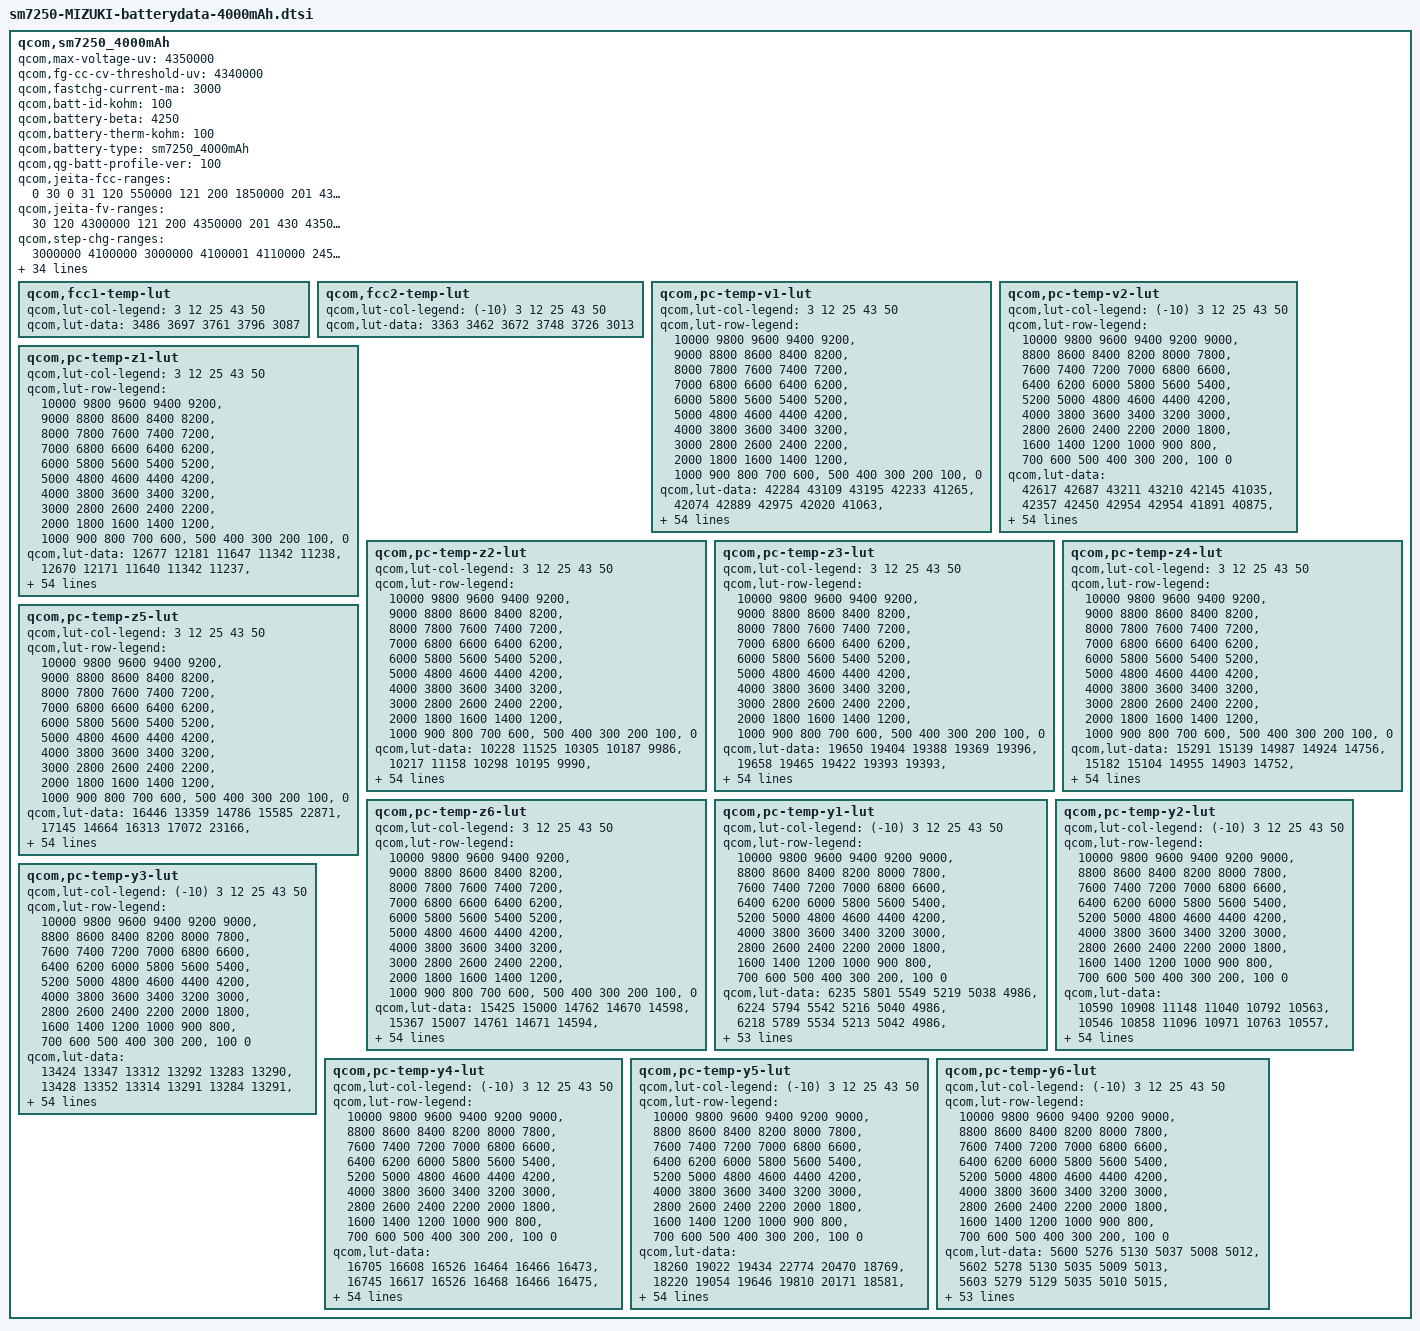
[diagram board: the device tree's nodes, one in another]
/*
 * This software is contributed or developed by KYOCERA Corporation.
 * (C) 2020 KYOCERA Corporation
 *
 * This program is free software; you can redistribute it and/or modify
 * it under the terms of the GNU General Public License version 2 and
 * only version 2 as published by the Free Software Foundation.
 *
 * This program is distributed in the hope that it will be useful,
 * but WITHOUT ANY WARRANTY; without even the implied warranty of
 * MERCHANTABILITY or FITNESS FOR A PARTICULAR PURPOSE.  See the
 * GNU General Public License for more details.
 */

qcom,sm7250_4000mAh {
	qcom,max-voltage-uv = <4350000>;
	qcom,fg-cc-cv-threshold-uv = <4340000>;
	qcom,fastchg-current-ma = <3000>;
	qcom,batt-id-kohm = <100>;
	qcom,battery-beta = <4250>;
	qcom,battery-therm-kohm = <100>;
	qcom,battery-type = "sm7250_4000mAh";
	qcom,qg-batt-profile-ver = <100>;

	qcom,jeita-fcc-ranges = <0  30  0
				 31 120  550000
				121 200  1850000
				201 430  3000000
				431 500  1850000
				501 600  0>;

	qcom,jeita-fv-ranges = <30 120  4300000
				121 200  4350000
				201 430  4350000
				431 500  4150000>;

	qcom,step-chg-ranges = <3000000  4100000  3000000
				4100001  4110000  2450000
				4110001  4120000  2450000
				4120001  4130000  2450000
				4130001  4140000  2450000
				4140001  4150000  2450000
				4150001  4350000  1200000>;
	qcom,step-chg-ranges-cool = <3000000  4350000  550000>;
	qcom,step-chg-ranges-weekcool = <3000000  4100000  1850000
				4100001  4150000  1450000
				4150001  4350000  1000000>;
	qcom,step-chg-ranges-normal = <3000000  4150000  3000000
				4150001  4250000  2250000
				4250001  4350000  1000000>;
	qcom,step-chg-ranges-warm = <3000000  4350000  1850000>;
	qcom,step-chg-temp-thresh = <30 100 200 430>;
	qcom,ocv-based-step-chg;

	/* COOL = 12 DegC, WARM = 43 DegC */
	qcom,jeita-soft-thresholds = <0x4A2A 0x22B8>;
	/* COLD = 3 DegC, HOT = 50 DegC */
	qcom,jeita-hard-thresholds = <0x5571 0x1C22>;
	/* COOL hys = 14 DegC, WARM hys = 41 DegC */
	qcom,jeita-soft-hys-thresholds = <0x477C 0x24CF>;
	qcom,jeita-soft-fcc-ua = <560000 1850000>;
	qcom,jeita-soft-fv-uv = <4300000 4150000>;

	oem,batt-capacity-mah = <4000>;
	oem,deterioration-thresh-good = <75>;
	oem,deterioration-thresh-norm = <50>;
	oem,deterioration-thresh-normtogood = <85>;
	oem,deterioration-thresh-deadtonorm = <60>;
	oem,cycle-count-thresh = <50 100 200 400 600>;
	oem,cycle-count-voltage-comp-mv = <40 80 120 160 200>;
	oem,cont-chg-thresh = <520000 840000 1200000 2200000 3300000>;
	oem,cont-chg-voltage-comp-mv = <40 80 120 160 200>;
	oem,batt-temp-thresh = <(-1250) 300 320 340 360 380 400 420 440 460>;
	oem,cont-chg-factor = <29 42 60 86 124 180 261 378 549 783>;
	oem,cont-chg-factor-batt-care = <15 21 30 43 62 90 131 189 275 392>;
	oem,batt-care-max-voltage-uv = <4200000>;

	qcom,fcc1-temp-lut {
		qcom,lut-col-legend = <3 12 25 43 50>;
		qcom,lut-data = <3486 3697 3761 3796 3087>;
	};

	qcom,fcc2-temp-lut {
		qcom,lut-col-legend = <(-10) 3 12 25 43 50>;
		qcom,lut-data = <3363 3462 3672 3748 3726 3013>;
	};

	qcom,pc-temp-v1-lut {
		qcom,lut-col-legend = <3 12 25 43 50>;
		qcom,lut-row-legend = <10000 9800 9600 9400 9200>,
			<9000 8800 8600 8400 8200>,
			<8000 7800 7600 7400 7200>,
			<7000 6800 6600 6400 6200>,
			<6000 5800 5600 5400 5200>,
			<5000 4800 4600 4400 4200>,
			<4000 3800 3600 3400 3200>,
			<3000 2800 2600 2400 2200>,
			<2000 1800 1600 1400 1200>,
			<1000 900 800 700 600>,
			<500 400 300 200 100>,
			<0>;
		qcom,lut-data = <42284 43109 43195 42233 41265>,
			<42074 42889 42975 42020 41063>,
			<41859 42668 42756 41806 40851>,
			<41643 42448 42540 41593 40638>,
			<41445 42231 42324 41379 40422>,
			<41282 42022 42111 41165 40205>,
			<41143 41816 41899 40951 39991>,
			<40998 41613 41690 40737 39778>,
			<40824 41412 41484 40527 39568>,
			<40621 41217 41279 40320 39361>,
			<40405 41040 41080 40117 39158>,
			<40181 40877 40892 39923 38960>,
			<39953 40706 40712 39734 38765>,
			<39742 40494 40530 39552 38578>,
			<39564 40264 40343 39372 38396>,
			<39411 40079 40160 39196 38220>,
			<39261 39950 40000 39031 38053>,
			<39099 39829 39865 38887 37905>,
			<38929 39660 39714 38737 37758>,
			<38773 39418 39496 38538 37573>,
			<38640 39187 39241 38287 37329>,
			<38522 39028 39048 38074 37106>,
			<38425 38904 38921 37932 36954>,
			<38352 38799 38815 37814 36831>,
			<38290 38710 38709 37707 36720>,
			<38233 38630 38609 37609 36619>,
			<38178 38550 38518 37519 36526>,
			<38129 38472 38436 37434 36439>,
			<38083 38398 38362 37354 36356>,
			<38042 38335 38294 37282 36280>,
			<38002 38278 38232 37218 36213>,
			<37962 38227 38175 37159 36150>,
			<37925 38183 38125 37104 36090>,
			<37885 38144 38079 37050 36030>,
			<37847 38108 38036 36998 35972>,
			<37810 38077 37997 36946 35913>,
			<37761 38043 37958 36894 35852>,
			<37698 37994 37907 36831 35781>,
			<37633 37919 37831 36748 35689>,
			<37559 37829 37740 36652 35584>,
			<37433 37730 37642 36550 35477>,
			<37296 37612 37530 36437 35365>,
			<37203 37474 37398 36301 35229>,
			<37114 37323 37248 36142 35064>,
			<37030 37193 37129 36036 34968>,
			<36953 37121 37053 35980 34921>,
			<36950 37100 37033 35957 34899>,
			<36931 37084 37017 35938 34880>,
			<36858 37062 36993 35914 34855>,
			<36697 36986 36915 35822 34750>,
			<36686 36737 36647 35516 34426>,
			<35946 36292 36201 35076 33989>,
			<35605 35730 35639 34516 33428>,
			<34343 34981 34884 33760 32669>,
			<33008 33773 33683 32559 31471>,
			<30000 30000 30000 30000 30000>;
	};

	qcom,pc-temp-v2-lut {
		qcom,lut-col-legend = <(-10) 3 12 25 43 50>;
		qcom,lut-row-legend = <10000 9800 9600 9400 9200 9000>,
			<8800 8600 8400 8200 8000 7800>,
			<7600 7400 7200 7000 6800 6600>,
			<6400 6200 6000 5800 5600 5400>,
			<5200 5000 4800 4600 4400 4200>,
			<4000 3800 3600 3400 3200 3000>,
			<2800 2600 2400 2200 2000 1800>,
			<1600 1400 1200 1000 900 800>,
			<700 600 500 400 300 200>,
			<100 0>;
		qcom,lut-data = <42617 42687 43211 43210 42145 41035>,
			<42357 42450 42954 42954 41891 40875>,
			<42125 42125 42706 42708 41648 40720>,
			<41907 42020 42471 42473 41415 40568>,
			<41680 41680 42248 42249 41195 33639>,
			<41448 41611 42030 42032 40980 40276>,
			<41245 41245 41815 41818 40766 34041>,
			<41099 41226 41604 41609 40555 39998>,
			<40983 40983 41397 41403 40348 34286>,
			<40847 40857 41193 41198 40143 39744>,
			<40647 40647 40992 40995 39942 34895>,
			<40399 40483 40798 40800 39748 39495>,
			<40147 40147 40611 40611 39562 32076>,
			<39900 40115 40426 40427 39381 39149>,
			<39663 39663 40242 40244 39205 34198>,
			<39453 39744 40058 40063 39033 38808>,
			<39271 39271 39873 39894 38869 35581>,
			<39104 39359 39682 39749 38720 38596>,
			<38944 38944 39490 39605 38573 36063>,
			<38792 38992 39298 39421 38394 38425>,
			<38648 38648 39098 39175 38155 36063>,
			<38512 38689 38911 38944 37923 38275>,
			<38383 38383 38763 38780 37762 36439>,
			<38279 38458 38636 38644 37632 38146>,
			<38206 38206 38524 38527 37518 36571>,
			<38147 38266 38421 38425 37414 38034>,
			<38095 38095 38329 38334 37321 36838>,
			<38047 38102 38243 38248 37237 37936>,
			<38006 38006 38165 38168 37160 36636>,
			<37965 37975 38092 38094 37090 37827>,
			<37928 37928 38023 38027 37027 36500>,
			<37890 37890 37955 37965 36968 37695>,
			<37850 37850 37895 37907 36908 36116>,
			<37810 37825 37842 37853 36844 37534>,
			<37766 37766 37793 37800 36775 36322>,
			<37720 37758 37746 37738 36696 37379>,
			<37671 37671 37703 37665 36601 36454>,
			<37611 37676 37655 37589 36504 37251>,
			<37545 37545 37589 37513 36422 36046>,
			<37471 37518 37504 37435 36346 37078>,
			<37377 37377 37407 37345 36262 35929>,
			<37245 37267 37289 37233 36145 36896>,
			<37128 37128 37161 37117 36020 36435>,
			<37056 37039 37058 37016 35928 36791>,
			<36980 36980 36977 36925 35859 36608>,
			<36910 36893 36916 36879 35811 36729>,
			<36883 36883 36897 36867 35799 36455>,
			<36885 36917 36879 36850 35784 36592>,
			<36819 36819 36837 36804 35744 34476>,
			<36664 36714 36667 36699 35566 36094>,
			<36369 36369 36382 36416 35279 33751>,
			<35968 35966 35886 35942 34785 35204>,
			<35107 35107 35242 35335 34167 32576>,
			<34213 34213 34368 34539 33348 33822>,
			<33148 33148 33148 33460 32211 33161>,
			<30000 30000 30000 29517 30000 30000>;
	};

	qcom,pc-temp-z1-lut {
		qcom,lut-col-legend = <3 12 25 43 50>;
		qcom,lut-row-legend = <10000 9800 9600 9400 9200>,
			<9000 8800 8600 8400 8200>,
			<8000 7800 7600 7400 7200>,
			<7000 6800 6600 6400 6200>,
			<6000 5800 5600 5400 5200>,
			<5000 4800 4600 4400 4200>,
			<4000 3800 3600 3400 3200>,
			<3000 2800 2600 2400 2200>,
			<2000 1800 1600 1400 1200>,
			<1000 900 800 700 600>,
			<500 400 300 200 100>,
			<0>;
		qcom,lut-data = <12677 12181 11647 11342 11238>,
			<12670 12171 11640 11342 11237>,
			<12656 12158 11633 11342 11238>,
			<12636 12144 11625 11341 11238>,
			<12619 12131 11617 11338 11238>,
			<12607 12119 11610 11334 11239>,
			<12597 12110 11604 11332 11239>,
			<12584 12105 11599 11330 11239>,
			<12569 12103 11597 11329 11239>,
			<12560 12102 11596 11328 11240>,
			<12560 12099 11595 11326 11241>,
			<12565 12093 11593 11326 11243>,
			<12568 12086 11589 11325 11244>,
			<12561 12076 11588 11325 11246>,
			<12547 12064 11588 11325 11246>,
			<12541 12061 11588 11325 11249>,
			<12546 12071 11589 11326 11253>,
			<12555 12083 11591 11327 11256>,
			<12561 12085 11595 11329 11259>,
			<12566 12083 11597 11330 11259>,
			<12570 12081 11599 11332 11262>,
			<12576 12085 11602 11334 11265>,
			<12582 12094 11606 11338 11267>,
			<12587 12100 11612 11342 11270>,
			<12589 12102 11618 11346 11270>,
			<12589 12103 11625 11350 11273>,
			<12591 12106 11631 11353 11277>,
			<12592 12112 11637 11357 11281>,
			<12591 12117 11642 11361 11284>,
			<12590 12122 11647 11365 11284>,
			<12593 12127 11653 11368 11288>,
			<12608 12131 11658 11372 11292>,
			<12623 12135 11663 11376 11295>,
			<12624 12139 11667 11381 11299>,
			<12618 12140 11672 11386 11303>,
			<12614 12140 11677 11390 11303>,
			<12618 12140 11683 11394 11307>,
			<12626 12142 11690 11398 11311>,
			<12634 12151 11699 11404 11316>,
			<12645 12161 11708 11409 11319>,
			<12656 12166 11714 11414 11319>,
			<12656 12170 11720 11419 11322>,
			<12661 12176 11724 11423 11326>,
			<12682 12185 11730 11427 11328>,
			<12681 12195 11742 11433 11328>,
			<12680 12193 11747 11434 11329>,
			<12696 12193 11748 11435 11333>,
			<12674 12200 11750 11439 11340>,
			<12674 12200 11752 11444 11348>,
			<12693 12209 11761 11450 11361>,
			<12719 12228 11773 11459 11361>,
			<12740 12239 11791 11474 11379>,
			<12763 12258 11810 11490 11405>,
			<12763 12306 11835 11517 11405>,
			<12763 12306 11835 11517 11405>,
			<12763 12306 11835 11517 11405>;
	};

	qcom,pc-temp-z2-lut {
		qcom,lut-col-legend = <3 12 25 43 50>;
		qcom,lut-row-legend = <10000 9800 9600 9400 9200>,
			<9000 8800 8600 8400 8200>,
			<8000 7800 7600 7400 7200>,
			<7000 6800 6600 6400 6200>,
			<6000 5800 5600 5400 5200>,
			<5000 4800 4600 4400 4200>,
			<4000 3800 3600 3400 3200>,
			<3000 2800 2600 2400 2200>,
			<2000 1800 1600 1400 1200>,
			<1000 900 800 700 600>,
			<500 400 300 200 100>,
			<0>;
		qcom,lut-data = <10228 11525 10305 10187 9986>,
			<10217 11158 10298 10195 9990>,
			<10199 10821 10287 10191 10003>,
			<10180 10489 10266 10174 10003>,
			<10168 10322 10236 10133 10015>,
			<10161 10287 10228 10101 10021>,
			<10157 10263 10426 10109 10026>,
			<10160 10260 10705 10128 10033>,
			<10176 10272 10794 10134 10033>,
			<10197 10289 10823 10099 10042>,
			<10218 10341 10836 10053 10055>,
			<10242 10502 10821 10037 10073>,
			<10253 10613 10785 10035 10099>,
			<10250 10540 10769 10036 10131>,
			<10246 10386 10792 10038 10131>,
			<10246 10323 10822 10040 10175>,
			<10263 10324 10771 10044 10226>,
			<10283 10327 10479 10059 10238>,
			<10285 10338 10252 10087 10116>,
			<10275 10376 10308 10166 10116>,
			<10266 10406 10439 10347 9963>,
			<10270 10392 10486 10450 9919>,
			<10287 10355 10414 10447 9899>,
			<10301 10338 10331 10437 9893>,
			<10306 10348 10321 10407 9893>,
			<10306 10362 10333 10253 9898>,
			<10310 10365 10342 10096 9906>,
			<10312 10360 10313 10044 9918>,
			<10313 10354 10255 10013 9951>,
			<10314 10350 10234 9994 9951>,
			<10317 10344 10237 9977 9995>,
			<10328 10341 10243 9962 10038>,
			<10341 10352 10252 9964 10086>,
			<10351 10376 10273 9994 10131>,
			<10360 10399 10299 10034 10178>,
			<10370 10421 10328 10079 10178>,
			<10386 10443 10363 10133 10216>,
			<10406 10468 10399 10173 10218>,
			<10414 10497 10445 10205 10190>,
			<10409 10517 10484 10226 10171>,
			<10404 10522 10496 10230 10171>,
			<10407 10525 10499 10228 10173>,
			<10428 10522 10483 10247 10137>,
			<10524 10521 10443 10320 10103>,
			<10517 10582 10440 10236 10101>,
			<10591 10569 10415 10210 10122>,
			<10455 10571 10421 10212 10194>,
			<10545 10585 10421 10219 10218>,
			<17220 10610 10431 10269 10040>,
			<19665 10668 10453 10318 9932>,
			<16762 10710 10411 10134 9932>,
			<14152 10702 10296 10031 9900>,
			<13754 10665 10265 10002 9837>,
			<13754 10618 10203 9934 9837>,
			<13754 10618 10203 9934 9837>,
			<13754 10618 10203 9934 9837>;
	};

	qcom,pc-temp-z3-lut {
		qcom,lut-col-legend = <3 12 25 43 50>;
		qcom,lut-row-legend = <10000 9800 9600 9400 9200>,
			<9000 8800 8600 8400 8200>,
			<8000 7800 7600 7400 7200>,
			<7000 6800 6600 6400 6200>,
			<6000 5800 5600 5400 5200>,
			<5000 4800 4600 4400 4200>,
			<4000 3800 3600 3400 3200>,
			<3000 2800 2600 2400 2200>,
			<2000 1800 1600 1400 1200>,
			<1000 900 800 700 600>,
			<500 400 300 200 100>,
			<0>;
		qcom,lut-data = <19650 19404 19388 19369 19396>,
			<19658 19465 19422 19393 19393>,
			<19660 19497 19443 19411 19390>,
			<19660 19521 19448 19416 19390>,
			<19660 19530 19450 19419 19387>,
			<19658 19530 19452 19420 19385>,
			<19655 19529 19455 19418 19382>,
			<19646 19527 19459 19414 19379>,
			<19626 19521 19458 19411 19379>,
			<19611 19514 19455 19408 19372>,
			<19611 19510 19451 19405 19365>,
			<19614 19507 19445 19400 19364>,
			<19616 19506 19437 19395 19368>,
			<19608 19505 19432 19390 19375>,
			<19595 19503 19430 19387 19375>,
			<19591 19499 19429 19384 19395>,
			<19593 19489 19423 19381 19427>,
			<19596 19479 19409 19376 19439>,
			<19596 19480 19399 19372 19434>,
			<19595 19493 19405 19373 19434>,
			<19594 19504 19419 19381 19426>,
			<19591 19497 19423 19391 19419>,
			<19585 19480 19410 19413 19413>,
			<19582 19472 19395 19439 19407>,
			<19583 19477 19400 19445 19407>,
			<19583 19485 19435 19441 19399>,
			<19586 19495 19459 19435 19390>,
			<19589 19508 19457 19429 19382>,
			<19592 19518 19451 19423 19375>,
			<19595 19517 19445 19415 19375>,
			<19595 19510 19438 19406 19368>,
			<19589 19502 19431 19397 19361>,
			<19582 19495 19424 19389 19355>,
			<19577 19487 19417 19382 19353>,
			<19573 19482 19410 19376 19358>,
			<19568 19477 19404 19369 19358>,
			<19562 19473 19398 19363 19365>,
			<19555 19469 19395 19361 19367>,
			<19548 19464 19393 19362 19368>,
			<19542 19460 19392 19363 19370>,
			<19536 19456 19391 19364 19370>,
			<19530 19453 19390 19367 19377>,
			<19520 19449 19388 19372 19374>,
			<19490 19442 19383 19380 19359>,
			<19481 19426 19375 19376 19350>,
			<19446 19420 19371 19356 19340>,
			<19281 19416 19362 19348 19327>,
			<19261 19404 19358 19345 19332>,
			<19258 19396 19355 19337 19359>,
			<19256 19391 19351 19335 19363>,
			<19257 19377 19365 19368 19363>,
			<19258 19366 19378 19375 19360>,
			<19259 19379 19379 19371 19363>,
			<19259 19360 19380 19372 19363>,
			<19259 19360 19380 19372 19363>,
			<19259 19360 19380 19372 19363>;
	};

	qcom,pc-temp-z4-lut {
		qcom,lut-col-legend = <3 12 25 43 50>;
		qcom,lut-row-legend = <10000 9800 9600 9400 9200>,
			<9000 8800 8600 8400 8200>,
			<8000 7800 7600 7400 7200>,
			<7000 6800 6600 6400 6200>,
			<6000 5800 5600 5400 5200>,
			<5000 4800 4600 4400 4200>,
			<4000 3800 3600 3400 3200>,
			<3000 2800 2600 2400 2200>,
			<2000 1800 1600 1400 1200>,
			<1000 900 800 700 600>,
			<500 400 300 200 100>,
			<0>;
		qcom,lut-data = <15291 15139 14987 14924 14756>,
			<15182 15104 14955 14903 14752>,
			<15104 15053 14922 14880 14747>,
			<15039 14990 14888 14854 14747>,
			<14988 14936 14852 14822 14742>,
			<14949 14893 14818 14794 14738>,
			<14914 14858 14780 14778 14734>,
			<14875 14833 14746 14765 14730>,
			<14830 14817 14732 14757 14730>,
			<14803 14803 14725 14751 14721>,
			<14818 14780 14720 14747 14712>,
			<14860 14748 14714 14742 14724>,
			<14884 14729 14708 14736 14807>,
			<14859 14744 14703 14730 14874>,
			<14815 14774 14700 14725 14874>,
			<14799 14785 14697 14721 14854>,
			<14803 14761 14695 14716 14801>,
			<14812 14734 14695 14707 14768>,
			<14843 14746 14701 14699 14754>,
			<14955 14834 14754 14725 14754>,
			<15051 14915 14854 14818 14744>,
			<15049 14941 14894 14873 14738>,
			<15016 14957 14898 14849 14733>,
			<14979 14962 14900 14804 14728>,
			<14949 14937 14888 14777 14728>,
			<14949 14893 14831 14761 14721>,
			<14920 14860 14783 14749 14714>,
			<14897 14831 14769 14741 14709>,
			<14881 14810 14760 14736 14703>,
			<14867 14803 14753 14731 14703>,
			<14857 14799 14747 14725 14700>,
			<14849 14796 14743 14720 14701>,
			<14842 14794 14741 14717 14703>,
			<14836 14792 14740 14713 14707>,
			<14830 14790 14739 14711 14719>,
			<14826 14785 14738 14712 14719>,
			<14822 14781 14737 14713 14732>,
			<14819 14781 14738 14715 14732>,
			<14814 14784 14747 14728 14723>,
			<14799 14786 14757 14741 14723>,
			<14778 14777 14753 14740 14723>,
			<14763 14757 14739 14726 14745>,
			<14743 14744 14736 14724 14710>,
			<14714 14732 14735 14730 14685>,
			<14699 14701 14706 14700 14675>,
			<14716 14687 14695 14693 14661>,
			<14880 14673 14685 14685 14648>,
			<14894 14667 14664 14664 14647>,
			<14896 14664 14650 14648 14693>,
			<14908 14671 14657 14652 14701>,
			<14918 14705 14673 14676 14701>,
			<14922 14725 14672 14681 14705>,
			<14927 14713 14675 14686 14702>,
			<14927 14737 14676 14686 14702>,
			<14927 14737 14676 14686 14702>,
			<14927 14737 14676 14686 14702>;
	};

	qcom,pc-temp-z5-lut {
		qcom,lut-col-legend = <3 12 25 43 50>;
		qcom,lut-row-legend = <10000 9800 9600 9400 9200>,
			<9000 8800 8600 8400 8200>,
			<8000 7800 7600 7400 7200>,
			<7000 6800 6600 6400 6200>,
			<6000 5800 5600 5400 5200>,
			<5000 4800 4600 4400 4200>,
			<4000 3800 3600 3400 3200>,
			<3000 2800 2600 2400 2200>,
			<2000 1800 1600 1400 1200>,
			<1000 900 800 700 600>,
			<500 400 300 200 100>,
			<0>;
		qcom,lut-data = <16446 13359 14786 15585 22871>,
			<17145 14664 16313 17072 23166>,
			<17893 15875 17407 18246 23652>,
			<18624 17163 17931 18968 23652>,
			<19460 18183 18259 19413 24264>,
			<20503 18879 18755 19840 25005>,
			<21560 19509 20317 20465 25939>,
			<22382 20177 22301 21204 26463>,
			<23041 20917 23469 21767 26463>,
			<23635 21634 24361 22213 26564>,
			<24301 22431 24831 22515 26533>,
			<24983 23618 24715 22535 26153>,
			<25306 24401 24439 22442 24652>,
			<25080 24332 24352 22375 23361>,
			<24748 24051 24994 22705 23361>,
			<25059 24197 25883 23517 23015>,
			<29932 24946 26153 24335 22783>,
			<35684 26187 25530 25342 22803>,
			<36656 28613 25151 26105 23333>,
			<35397 34083 26189 26100 23333>,
			<33574 38055 27915 25737 24090>,
			<31122 34574 28313 25215 24785>,
			<27621 25530 23056 23794 25612>,
			<25659 20864 16945 21944 26048>,
			<25674 20598 16598 21511 26048>,
			<25674 20454 19301 22177 25879>,
			<25805 20777 21919 23033 25585>,
			<26063 23789 23214 23742 25526>,
			<27835 27373 24205 24548 25787>,
			<30453 29303 25069 24880 25787>,
			<32146 30728 26211 24637 26038>,
			<33277 31780 27286 24302 25913>,
			<34171 32552 28025 24322 25470>,
			<34916 33153 29047 24897 25146>,
			<35609 33546 29630 25379 24908>,
			<35972 33850 29526 25364 24908>,
			<35793 34044 29241 25230 24654>,
			<35219 33795 28858 25016 24490>,
			<34509 32382 27860 24149 24298>,
			<33210 30958 26587 23131 24776>,
			<31951 30257 25574 22779 24776>,
			<31307 29616 24633 22624 28004>,
			<31159 28522 23443 23258 29060>,
			<32069 27504 22287 26193 21536>,
			<28042 28735 22359 26868 19497>,
			<19909 27110 21600 19424 19120>,
			<11967 26790 20816 18477 19402>,
			<11370 24233 22055 20213 22492>,
			<11384 22365 23743 21512 21645>,
			<11376 20839 21657 21577 18469>,
			<11338 17189 20245 24525 18469>,
			<11295 15164 20795 21591 16314>,
			<11224 15864 19809 18487 15322>,
			<11224 14169 18904 17303 15322>,
			<11224 14169 18904 17303 15322>,
			<11224 14169 18904 17303 15322>;
	};

	qcom,pc-temp-z6-lut {
		qcom,lut-col-legend = <3 12 25 43 50>;
		qcom,lut-row-legend = <10000 9800 9600 9400 9200>,
			<9000 8800 8600 8400 8200>,
			<8000 7800 7600 7400 7200>,
			<7000 6800 6600 6400 6200>,
			<6000 5800 5600 5400 5200>,
			<5000 4800 4600 4400 4200>,
			<4000 3800 3600 3400 3200>,
			<3000 2800 2600 2400 2200>,
			<2000 1800 1600 1400 1200>,
			<1000 900 800 700 600>,
			<500 400 300 200 100>,
			<0>;
		qcom,lut-data = <15425 15000 14762 14670 14598>,
			<15367 15007 14761 14671 14594>,
			<15320 14998 14759 14671 14590>,
			<15277 14972 14750 14669 14590>,
			<15242 14947 14732 14657 14586>,
			<15213 14924 14716 14643 14583>,
			<15187 14901 14702 14634 14580>,
			<15154 14885 14689 14627 14576>,
			<15114 14873 14681 14620 14576>,
			<15088 14862 14677 14616 14569>,
			<15090 14847 14672 14612 14561>,
			<15101 14829 14665 14607 14566>,
			<15108 14818 14657 14601 14605>,
			<15094 14822 14652 14595 14637>,
			<15070 14829 14650 14592 14637>,
			<15062 14831 14648 14588 14637>,
			<15067 14818 14644 14584 14634>,
			<15076 14802 14637 14578 14631>,
			<15095 14809 14633 14572 14624>,
			<15145 14857 14658 14585 14624>,
			<15186 14898 14710 14631 14615>,
			<15185 14903 14730 14659 14609>,
			<15170 14905 14727 14658 14604>,
			<15155 14905 14722 14655 14599>,
			<15144 14898 14718 14651 14599>,
			<15144 14886 14713 14644 14592>,
			<15134 14879 14709 14635 14584>,
			<15128 14876 14703 14629 14578>,
			<15125 14873 14697 14624 14572>,
			<15123 14869 14692 14618 14572>,
			<15120 14865 14687 14612 14567>,
			<15117 14861 14682 14605 14564>,
			<15113 14858 14678 14599 14562>,
			<15112 14855 14674 14594 14561>,
			<15111 14853 14671 14590 14568>,
			<15110 14851 14668 14587 14568>,
			<15111 14849 14665 14585 14578>,
			<15113 14849 14664 14584 14579>,
			<15113 14852 14669 14590 14577>,
			<15111 14854 14673 14597 14578>,
			<15108 14851 14672 14597 14578>,
			<15108 14845 14668 14594 14592>,
			<15107 14842 14666 14595 14576>,
			<15092 14839 14665 14604 14558>,
			<15086 14824 14651 14590 14549>,
			<15078 14817 14645 14577 14539>,
			<15071 14810 14637 14569 14525>,
			<15072 14803 14626 14559 14528>,
			<15080 14801 14619 14547 14566>,
			<15095 14806 14622 14549 14575>,
			<15112 14820 14640 14580 14575>,
			<15127 14831 14650 14590 14580>,
			<15150 14840 14656 14594 14586>,
			<15150 14854 14665 14600 14586>,
			<15150 14854 14665 14600 14586>,
			<15150 14854 14665 14600 14586>;
	};

	qcom,pc-temp-y1-lut {
		qcom,lut-col-legend = <(-10) 3 12 25 43 50>;
		qcom,lut-row-legend = <10000 9800 9600 9400 9200 9000>,
			<8800 8600 8400 8200 8000 7800>,
			<7600 7400 7200 7000 6800 6600>,
			<6400 6200 6000 5800 5600 5400>,
			<5200 5000 4800 4600 4400 4200>,
			<4000 3800 3600 3400 3200 3000>,
			<2800 2600 2400 2200 2000 1800>,
			<1600 1400 1200 1000 900 800>,
			<700 600 500 400 300 200>,
			<100 0>;
		qcom,lut-data = <6235 5801 5549 5219 5038 4986>,
			<6224 5794 5542 5216 5040 4986>,
			<6218 5789 5534 5213 5042 4986>,
			<6214 5785 5527 5210 5043 4986>,
			<6215 5785 5521 5208 5044 4986>,
			<6222 5786 5515 5206 5044 4986>,
			<6229 5786 5511 5205 5043 4986>,
			<6236 5785 5507 5204 5042 4986>,
			<6242 5782 5504 5203 5042 4986>,
			<6243 5782 5501 5201 5041 4987>,
			<6232 5780 5499 5199 5041 4989>,
			<6221 5779 5497 5197 5041 4990>,
			<6225 5781 5492 5194 5040 4991>,
			<6240 5786 5488 5192 5040 4992>,
			<6250 5789 5488 5193 5040 4992>,
			<6247 5790 5491 5195 5041 4993>,
			<6238 5790 5493 5197 5042 4995>,
			<6236 5791 5495 5198 5043 4997>,
			<6237 5794 5497 5199 5043 4999>,
			<6238 5798 5497 5200 5044 4999>,
			<6236 5798 5496 5202 5045 5001>,
			<6228 5799 5494 5205 5046 5003>,
			<6222 5799 5494 5208 5048 5005>,
			<6219 5796 5494 5212 5051 5008>,
			<6218 5792 5495 5216 5053 5008>,
			<6218 5792 5498 5218 5055 5011>,
			<6218 5791 5502 5221 5058 5013>,
			<6225 5792 5504 5224 5060 5015>,
			<6232 5793 5506 5230 5063 5017>,
			<6230 5794 5507 5236 5066 5017>,
			<6218 5796 5510 5240 5069 5019>,
			<6211 5798 5516 5244 5072 5021>,
			<6214 5801 5520 5249 5076 5022>,
			<6220 5804 5521 5253 5079 5024>,
			<6221 5806 5521 5258 5081 5026>,
			<6213 5804 5524 5261 5084 5026>,
			<6202 5801 5532 5263 5085 5028>,
			<6197 5801 5542 5266 5087 5030>,
			<6194 5802 5549 5269 5089 5033>,
			<6192 5803 5556 5272 5090 5035>,
			<6193 5805 5560 5277 5093 5035>,
			<6196 5808 5560 5284 5096 5037>,
			<6196 5809 5559 5292 5100 5040>,
			<6190 5809 5560 5299 5104 5041>,
			<6185 5808 5564 5305 5109 5042>,
			<6186 5808 5572 5311 5111 5042>,
			<6188 5808 5580 5313 5111 5042>,
			<6191 5809 5589 5315 5111 5044>,
			<6200 5814 5592 5313 5111 5047>,
			<6215 5824 5589 5310 5112 5053>,
			<6246 5848 5586 5312 5114 5053>,
			<6269 5849 5593 5317 5121 5062>,
			<6301 5859 5604 5330 5129 5075>,
			<6301 5859 5620 5348 5144 5075>,
			<6301 5859 5620 5348 5144 5075>,
			<6301 5859 5620 5348 5144 5075>;
	};

	qcom,pc-temp-y2-lut {
		qcom,lut-col-legend = <(-10) 3 12 25 43 50>;
		qcom,lut-row-legend = <10000 9800 9600 9400 9200 9000>,
			<8800 8600 8400 8200 8000 7800>,
			<7600 7400 7200 7000 6800 6600>,
			<6400 6200 6000 5800 5600 5400>,
			<5200 5000 4800 4600 4400 4200>,
			<4000 3800 3600 3400 3200 3000>,
			<2800 2600 2400 2200 2000 1800>,
			<1600 1400 1200 1000 900 800>,
			<700 600 500 400 300 200>,
			<100 0>;
		qcom,lut-data = <10590 10908 11148 11040 10792 10563>,
			<10546 10858 11096 10971 10763 10557>,
			<10526 10813 11045 10898 10734 10549>,
			<10522 10784 10997 10831 10705 10549>,
			<10533 10774 10954 10779 10680 10542>,
			<10579 10768 10918 10753 10661 10548>,
			<10627 10766 10891 10758 10649 10574>,
			<10666 10773 10867 10781 10640 10612>,
			<10704 10791 10852 10793 10631 10612>,
			<10727 10818 10844 10788 10617 10703>,
			<10740 10877 10838 10781 10603 10825>,
			<10753 10943 10842 10778 10600 10866>,
			<10779 10985 10898 10783 10622 10861>,
			<10825 11021 10975 10792 10644 10851>,
			<10851 11039 11034 10814 10647 10851>,
			<10851 11038 11092 10864 10650 10846>,
			<10850 11033 11132 10928 10660 10835>,
			<10850 11034 11154 11037 10757 10828>,
			<10844 11048 11170 11145 10903 10838>,
			<10837 11065 11173 11162 10941 10838>,
			<10835 11076 11167 11131 10924 10863>,
			<10833 11085 11161 11102 10906 10889>,
			<10832 11092 11165 11089 10905 10923>,
			<10833 11098 11182 11069 10910 10956>,
			<10833 11103 11201 11062 10915 10956>,
			<10833 11103 11216 11101 10930 10979>,
			<10801 11113 11230 11158 10954 11004>,
			<10370 11141 11241 11188 10974 11024>,
			<9879 11168 11250 11205 11002 11048>,
			<9775 11166 11256 11222 11027 11048>,
			<9749 11146 11259 11246 11035 11075>,
			<9731 11126 11262 11275 11040 11076>,
			<9715 11114 11265 11290 11049 11000>,
			<9699 11101 11270 11297 11087 10909>,
			<9690 11087 11274 11302 11138 10874>,
			<9684 11069 11274 11289 11140 10874>,
			<9680 11047 11263 11227 11044 10855>,
			<9676 11019 11246 11177 10950 10837>,
			<9672 10980 11229 11171 10943 10818>,
			<9670 10933 11207 11172 10963 10796>,
			<9668 10884 11179 11172 10969 10796>,
			<9667 10820 11138 11161 10948 10754>,
			<9665 10684 11084 11143 10912 10637>,
			<9664 10156 11026 11088 10853 10587>,
			<9662 9805 10956 10971 10727 10681>,
			<9662 9774 10908 10948 10687 10804>,
			<9661 9753 10898 10955 10735 10852>,
			<9660 9735 10888 10960 10786 10707>,
			<9660 9714 10873 10958 10799 10559>,
			<9659 9701 10844 10956 10774 10528>,
			<9658 9700 10811 10964 10727 10528>,
			<9657 9686 10773 10934 10618 10454>,
			<9653 9676 10724 10856 10562 10335>,
			<9653 9676 10680 10779 10490 10335>,
			<9653 9676 10680 10779 10490 10335>,
			<9653 9676 10680 10779 10490 10335>;
	};

	qcom,pc-temp-y3-lut {
		qcom,lut-col-legend = <(-10) 3 12 25 43 50>;
		qcom,lut-row-legend = <10000 9800 9600 9400 9200 9000>,
			<8800 8600 8400 8200 8000 7800>,
			<7600 7400 7200 7000 6800 6600>,
			<6400 6200 6000 5800 5600 5400>,
			<5200 5000 4800 4600 4400 4200>,
			<4000 3800 3600 3400 3200 3000>,
			<2800 2600 2400 2200 2000 1800>,
			<1600 1400 1200 1000 900 800>,
			<700 600 500 400 300 200>,
			<100 0>;
		qcom,lut-data = <13424 13347 13312 13292 13283 13290>,
			<13428 13352 13314 13291 13284 13291>,
			<13431 13356 13315 13290 13285 13293>,
			<13433 13360 13317 13290 13286 13293>,
			<13433 13364 13319 13290 13286 13294>,
			<13433 13368 13321 13291 13287 13295>,
			<13433 13370 13323 13293 13288 13295>,
			<13422 13370 13326 13297 13289 13295>,
			<13405 13369 13328 13300 13290 13295>,
			<13400 13368 13330 13302 13290 13296>,
			<13406 13360 13331 13303 13291 13297>,
			<13413 13352 13332 13303 13291 13296>,
			<13412 13352 13331 13304 13294 13290>,
			<13404 13353 13330 13304 13296 13283>,
			<13395 13354 13328 13305 13297 13283>,
			<13389 13351 13325 13306 13297 13282>,
			<13384 13345 13322 13306 13298 13282>,
			<13379 13340 13320 13305 13298 13282>,
			<13376 13337 13318 13303 13297 13282>,
			<13372 13334 13316 13300 13296 13282>,
			<13364 13331 13313 13296 13290 13282>,
			<13349 13329 13311 13292 13285 13283>,
			<13339 13327 13309 13290 13283 13283>,
			<13340 13326 13307 13289 13283 13284>,
			<13341 13324 13306 13288 13283 13284>,
			<13341 13324 13305 13288 13282 13284>,
			<13342 13322 13305 13288 13281 13283>,
			<13344 13317 13304 13288 13281 13283>,
			<13348 13312 13304 13288 13281 13284>,
			<13354 13312 13303 13287 13281 13284>,
			<13366 13315 13303 13287 13281 13284>,
			<13378 13318 13304 13287 13282 13285>,
			<13386 13321 13304 13287 13283 13284>,
			<13394 13324 13303 13288 13284 13283>,
			<13404 13326 13303 13288 13285 13283>,
			<13418 13328 13303 13288 13285 13283>,
			<13433 13329 13304 13288 13284 13285>,
			<13448 13330 13305 13287 13283 13286>,
			<13465 13330 13305 13287 13284 13285>,
			<13486 13331 13304 13288 13286 13283>,
			<13514 13332 13304 13288 13286 13283>,
			<13551 13333 13305 13289 13285 13283>,
			<13598 13335 13305 13289 13283 13287>,
			<13663 13340 13306 13290 13283 13293>,
			<13742 13350 13309 13292 13287 13297>,
			<13787 13362 13315 13298 13293 13302>,
			<13837 13377 13322 13304 13298 13304>,
			<13885 13391 13329 13308 13302 13299>,
			<13939 13406 13333 13309 13302 13293>,
			<13978 13415 13334 13309 13300 13292>,
			<13955 13396 13335 13301 13296 13292>,
			<14089 13416 13327 13300 13293 13298>,
			<14408 13461 13331 13304 13298 13308>,
			<14408 13461 13342 13310 13307 13308>,
			<14408 13461 13342 13310 13307 13308>,
			<14408 13461 13342 13310 13307 13308>;
	};

	qcom,pc-temp-y4-lut {
		qcom,lut-col-legend = <(-10) 3 12 25 43 50>;
		qcom,lut-row-legend = <10000 9800 9600 9400 9200 9000>,
			<8800 8600 8400 8200 8000 7800>,
			<7600 7400 7200 7000 6800 6600>,
			<6400 6200 6000 5800 5600 5400>,
			<5200 5000 4800 4600 4400 4200>,
			<4000 3800 3600 3400 3200 3000>,
			<2800 2600 2400 2200 2000 1800>,
			<1600 1400 1200 1000 900 800>,
			<700 600 500 400 300 200>,
			<100 0>;
		qcom,lut-data = <16705 16608 16526 16464 16466 16473>,
			<16745 16617 16526 16468 16466 16475>,
			<16781 16625 16527 16472 16465 16477>,
			<16808 16632 16528 16476 16466 16477>,
			<16825 16638 16530 16480 16466 16480>,
			<16836 16642 16532 16481 16466 16483>,
			<16852 16648 16534 16481 16467 16488>,
			<16953 16665 16537 16480 16468 16496>,
			<17105 16693 16540 16479 16469 16496>,
			<17146 16724 16545 16481 16471 16517>,
			<17065 16768 16553 16485 16475 16546>,
			<16952 16802 16566 16491 16477 16552>,
			<16869 16802 16594 16500 16480 16521>,
			<16792 16785 16628 16510 16482 16486>,
			<16738 16762 16655 16519 16487 16486>,
			<16711 16731 16683 16528 16494 16475>,
			<16693 16688 16696 16541 16504 16469>,
			<16669 16648 16679 16573 16530 16466>,
			<16633 16605 16643 16608 16562 16467>,
			<16601 16568 16605 16607 16566 16467>,
			<16586 16549 16559 16551 16528 16469>,
			<16578 16536 16520 16499 16487 16472>,
			<16573 16527 16507 16483 16475 16477>,
			<16570 16518 16499 16473 16468 16485>,
			<16568 16510 16496 16470 16465 16485>,
			<16568 16510 16496 16473 16468 16495>,
			<16569 16507 16497 16478 16472 16511>,
			<16595 16506 16498 16483 16478 16519>,
			<16625 16506 16501 16489 16486 16520>,
			<16635 16508 16504 16495 16495 16520>,
			<16638 16511 16504 16501 16506 16520>,
			<16642 16516 16503 16508 16517 16519>,
			<16652 16524 16503 16512 16522 16503>,
			<16665 16538 16504 16513 16521 16486>,
			<16675 16551 16507 16514 16520 16487>,
			<16681 16570 16511 16511 16515 16487>,
			<16687 16583 16517 16497 16496 16497>,
			<16692 16584 16523 16486 16478 16504>,
			<16697 16581 16522 16485 16479 16491>,
			<16698 16575 16519 16484 16486 16468>,
			<16679 16563 16516 16482 16490 16468>,
			<16649 16548 16514 16478 16479 16462>,
			<16639 16544 16512 16474 16464 16488>,
			<16658 16559 16512 16474 16462 16534>,
			<16696 16588 16520 16478 16477 16588>,
			<16747 16624 16538 16501 16512 16647>,
			<16809 16671 16575 16542 16572 16669>,
			<16841 16703 16619 16583 16630 16603>,
			<16840 16722 16643 16621 16642 16523>,
			<16833 16730 16655 16652 16596 16489>,
			<16733 16652 16654 16537 16534 16489>,
			<16784 16658 16562 16496 16482 16485>,
			<17057 16693 16576 16504 16483 16512>,
			<17057 16693 16623 16545 16511 16512>,
			<17057 16693 16623 16545 16511 16512>,
			<17057 16693 16623 16545 16511 16512>;
	};

	qcom,pc-temp-y5-lut {
		qcom,lut-col-legend = <(-10) 3 12 25 43 50>;
		qcom,lut-row-legend = <10000 9800 9600 9400 9200 9000>,
			<8800 8600 8400 8200 8000 7800>,
			<7600 7400 7200 7000 6800 6600>,
			<6400 6200 6000 5800 5600 5400>,
			<5200 5000 4800 4600 4400 4200>,
			<4000 3800 3600 3400 3200 3000>,
			<2800 2600 2400 2200 2000 1800>,
			<1600 1400 1200 1000 900 800>,
			<700 600 500 400 300 200>,
			<100 0>;
		qcom,lut-data = <18260 19022 19434 22774 20470 18769>,
			<18220 19054 19646 19810 20171 18581>,
			<17905 19050 19697 17763 19837 18437>,
			<17413 19022 19619 16475 19485 18437>,
			<16577 18962 19442 15787 19129 18187>,
			<15142 18805 19200 15541 18788 17709>,
			<14335 18556 18896 15929 18476 16764>,
			<14630 17298 18482 17157 18170 16147>,
			<15417 15425 17991 17830 17797 16147>,
			<16710 14888 17354 17564 17093 16039>,
			<20519 15342 16622 17055 16325 16005>,
			<24057 16163 15974 16561 16169 16199>,
			<24167 17674 15295 15798 16633 17871>,
			<23146 20550 14835 15166 17086 19575>,
			<22488 22520 15093 14969 16841 19575>,
			<22633 22991 16318 14828 15922 19778>,
			<22949 23300 17828 14780 15389 19770>,
			<23215 23610 19690 15051 15403 19726>,
			<23545 24136 21775 15660 15445 19021>,
			<23808 24566 23141 16829 15725 19021>,
			<22585 24486 24156 19909 17815 17761>,
			<17734 23985 24765 22241 19815 17092>,
			<14492 23551 24666 21951 19918 16773>,
			<14513 23378 24128 20976 19653 16593>,
			<14596 23205 23615 20383 19258 16593>,
			<14596 23205 23199 19991 18157 16619>,
			<14579 22719 22800 19585 16709 16830>,
			<13899 19810 22621 19341 16122 17172>,
			<13144 16829 22626 18953 15909 18406>,
			<13151 16667 22727 18688 15801 18406>,
			<13610 17533 23041 18735 15956 20279>,
			<13993 18501 23720 18899 16603 21158>,
			<14106 19489 24093 19158 17480 21482>,
			<14177 20537 23709 20304 19197 21677>,
			<14242 21054 23021 21522 21156 21750>,
			<14428 21388 22677 21633 21691 21750>,
			<14624 21626 22569 21328 21681 21782>,
			<14672 21650 22457 21039 21644 21797>,
			<14639 21619 22011 20786 21720 21805>,
			<14568 21634 20968 20477 21940 21758>,
			<14272 21764 20166 20408 22027 21758>,
			<13744 21923 19840 20758 21724 21290>,
			<13524 21685 19611 21133 21123 17645>,
			<13588 17680 19440 20809 20299 14795>,
			<13633 14860 19272 19356 18238 14140>,
			<13687 14618 18951 17848 16122 13650>,
			<13799 14454 18415 17004 15029 13481>,
			<13911 14403 17770 16216 14183 13813>,
			<14046 14499 17329 15470 13989 14476>,
			<14209 14703 17021 14898 14159 15698>,
			<14369 15067 17083 18973 14855 15698>,
			<13580 14999 21285 21478 17860 17263>,
			<12132 15993 21495 21729 18967 25131>,
			<12132 15993 22851 23917 25180 25131>,
			<12132 15993 22851 23917 25180 25131>,
			<12132 15993 22851 23917 25180 25131>;
	};

	qcom,pc-temp-y6-lut {
		qcom,lut-col-legend = <(-10) 3 12 25 43 50>;
		qcom,lut-row-legend = <10000 9800 9600 9400 9200 9000>,
			<8800 8600 8400 8200 8000 7800>,
			<7600 7400 7200 7000 6800 6600>,
			<6400 6200 6000 5800 5600 5400>,
			<5200 5000 4800 4600 4400 4200>,
			<4000 3800 3600 3400 3200 3000>,
			<2800 2600 2400 2200 2000 1800>,
			<1600 1400 1200 1000 900 800>,
			<700 600 500 400 300 200>,
			<100 0>;
		qcom,lut-data = <5600 5276 5130 5037 5008 5012>,
			<5602 5278 5130 5035 5009 5013>,
			<5603 5279 5129 5035 5010 5015>,
			<5603 5280 5129 5035 5011 5015>,
			<5602 5281 5130 5036 5012 5016>,
			<5596 5281 5130 5037 5013 5018>,
			<5593 5282 5130 5038 5014 5020>,
			<5609 5284 5131 5040 5014 5022>,
			<5638 5288 5132 5042 5015 5022>,
			<5646 5293 5133 5044 5016 5029>,
			<5630 5298 5135 5046 5018 5037>,
			<5606 5302 5138 5048 5019 5039>,
			<5586 5302 5144 5050 5021 5025>,
			<5564 5299 5151 5053 5024 5009>,
			<5548 5295 5157 5056 5026 5009>,
			<5537 5285 5163 5059 5028 5005>,
			<5529 5268 5166 5063 5031 5004>,
			<5521 5253 5160 5071 5038 5003>,
			<5513 5239 5147 5080 5047 5003>,
			<5505 5227 5134 5078 5047 5003>,
			<5499 5222 5118 5059 5032 5004>,
			<5494 5218 5106 5041 5015 5005>,
			<5491 5216 5101 5036 5011 5007>,
			<5495 5215 5099 5032 5009 5010>,
			<5506 5215 5098 5031 5008 5010>,
			<5506 5215 5098 5032 5009 5013>,
			<5517 5215 5099 5034 5010 5018>,
			<5529 5215 5100 5036 5012 5020>,
			<5543 5215 5101 5038 5014 5021>,
			<5559 5217 5103 5040 5017 5021>,
			<5577 5226 5104 5042 5020 5022>,
			<5598 5236 5106 5044 5024 5022>,
			<5620 5247 5107 5046 5027 5017>,
			<5644 5260 5109 5048 5027 5011>,
			<5669 5274 5112 5049 5028 5012>,
			<5696 5289 5115 5049 5027 5012>,
			<5724 5305 5120 5045 5021 5017>,
			<5751 5320 5125 5042 5016 5020>,
			<5777 5334 5128 5042 5017 5015>,
			<5805 5348 5131 5043 5020 5008>,
			<5834 5363 5134 5044 5022 5008>,
			<5867 5380 5138 5044 5019 5007>,
			<5909 5401 5145 5044 5014 5017>,
			<5973 5427 5154 5046 5013 5036>,
			<6055 5465 5168 5051 5021 5055>,
			<6110 5496 5190 5064 5037 5076>,
			<6173 5534 5213 5080 5057 5083>,
			<6230 5566 5237 5095 5076 5060>,
			<6286 5597 5252 5107 5080 5034>,
			<6323 5615 5261 5115 5066 5024>,
			<6298 5587 5263 5076 5046 5024>,
			<6464 5628 5222 5064 5028 5028>,
			<6888 5699 5246 5072 5034 5045>,
			<6888 5699 5287 5092 5051 5045>,
			<6888 5699 5287 5092 5051 5045>,
			<6888 5699 5287 5092 5051 5045>;
	};
};
